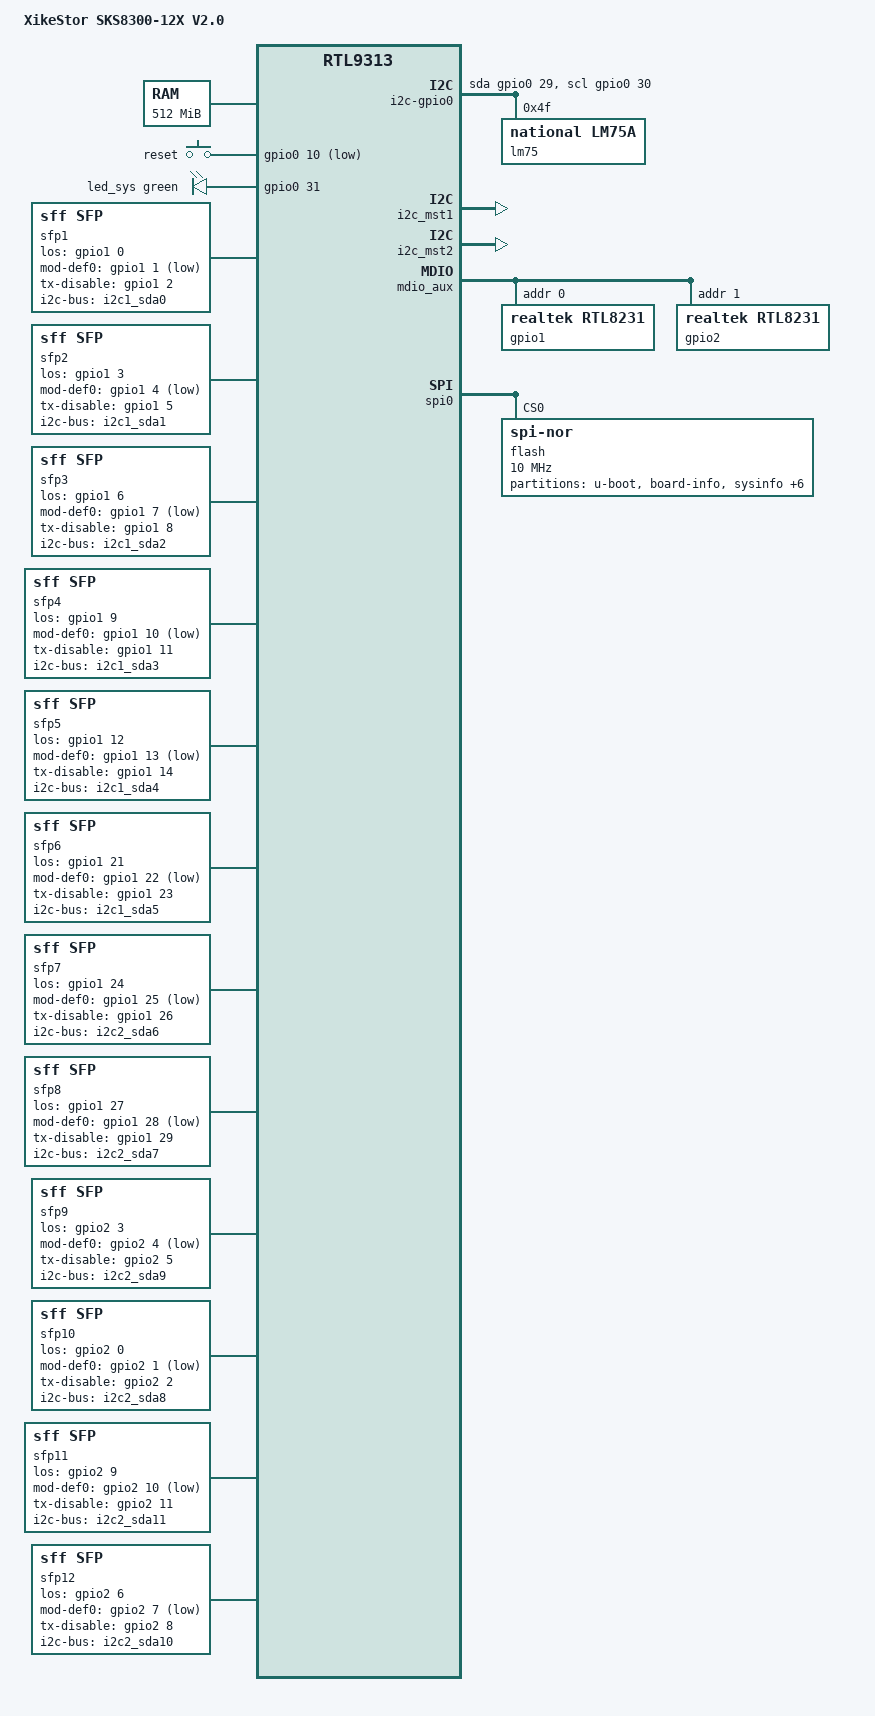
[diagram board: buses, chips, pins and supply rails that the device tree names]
// SPDX-License-Identifier: GPL-2.0-or-later

#include "rtl931x.dtsi"

#include <dt-bindings/input/input.h>
#include <dt-bindings/gpio/gpio.h>
#include <dt-bindings/leds/common.h>
#include <dt-bindings/phy/phy.h>

/ {
        compatible = "xikestor,sks8300-12x-v2", "realtek,rtl9313-soc";
        model = "XikeStor SKS8300-12X V2.0";

        memory@0 {
                device_type = "memory";
                reg = <0x00000000 0x10000000>, /* first 256 MiB */
                      <0x90000000 0x10000000>; /* remaining 256 MiB */
        };

        aliases {
                label-mac-device = &ethernet0;
                led-boot = &led_sys;
                led-failsafe = &led_sys;
                led-running = &led_sys;
                led-upgrade = &led_sys;
        };

        chosen {
                stdout-path = "serial0:115200n8";
                bootargs = "loglevel=4";
        };

        keys {
                compatible = "gpio-keys";

                button-reset {
                        label = "reset";
                        gpios = <&gpio0 10 GPIO_ACTIVE_LOW>;
                        linux,code = <KEY_RESTART>;
                };
        };

        leds {
                compatible = "gpio-leds";

                led_sys: led-0 {
                        gpios = <&gpio0 31 GPIO_ACTIVE_HIGH>;
                        color = <LED_COLOR_ID_GREEN>;
                        function = LED_FUNCTION_STATUS;
                };
        };

        led_set {
                compatible = "realtek,rtl9300-leds";
                active-low;

                /* LED[0]: green | LED[1]: amber */
                led_set0 = <(RTL93XX_LED_SET_10G | RTL93XX_LED_SET_LINK |
                             RTL93XX_LED_SET_ACT)
                            (RTL93XX_LED_SET_2P5G | RTL93XX_LED_SET_1G |
                             RTL93XX_LED_SET_LINK | RTL93XX_LED_SET_ACT)>;
        };

        watchdog1: watchdog {
                compatible = "diodes,pt7a75xx-wdt";
        };

        i2c-gpio0 {
                compatible = "i2c-gpio";
                #address-cells = <1>;
                #size-cells = <0>;

                sda-gpios = <&gpio0 29 GPIO_ACTIVE_HIGH>;
                scl-gpios = <&gpio0 30 GPIO_ACTIVE_HIGH>;

                i2c-gpio,delay-us = <5>;        /* ~100 kHz */
                lm75: sensor@4f {
                        compatible = "national,lm75a";
                        reg = <0x4f>;
                };
        };

        sfp1: sfp-p1 {
                compatible = "sff,sfp";
                i2c-bus = <&i2c1_sda0>;
                los-gpio = <&gpio1 0 GPIO_ACTIVE_HIGH>;
                mod-def0-gpio = <&gpio1 1 GPIO_ACTIVE_LOW>;
                tx-disable-gpio = <&gpio1 2 GPIO_ACTIVE_HIGH>;
                #thermal-sensor-cells = <0>;
        };

        sfp2: sfp-p2 {
                compatible = "sff,sfp";
                i2c-bus = <&i2c1_sda1>;
                los-gpio = <&gpio1 3 GPIO_ACTIVE_HIGH>;
                mod-def0-gpio = <&gpio1 4 GPIO_ACTIVE_LOW>;
                tx-disable-gpio = <&gpio1 5 GPIO_ACTIVE_HIGH>;
                #thermal-sensor-cells = <0>;
        };

        sfp3: sfp-p3 {
                compatible = "sff,sfp";
                i2c-bus = <&i2c1_sda2>;
                los-gpio = <&gpio1 6 GPIO_ACTIVE_HIGH>;
                mod-def0-gpio = <&gpio1 7 GPIO_ACTIVE_LOW>;
                tx-disable-gpio = <&gpio1 8 GPIO_ACTIVE_HIGH>;
                #thermal-sensor-cells = <0>;
        };

        sfp4: sfp-p4 {
                compatible = "sff,sfp";
                i2c-bus = <&i2c1_sda3>;
                los-gpio = <&gpio1 9 GPIO_ACTIVE_HIGH>;
                mod-def0-gpio = <&gpio1 10 GPIO_ACTIVE_LOW>;
                tx-disable-gpio = <&gpio1 11 GPIO_ACTIVE_HIGH>;
                #thermal-sensor-cells = <0>;
        };

        sfp5: sfp-p5 {
                compatible = "sff,sfp";
                i2c-bus = <&i2c1_sda4>;
                los-gpio = <&gpio1 12 GPIO_ACTIVE_HIGH>;
                mod-def0-gpio = <&gpio1 13 GPIO_ACTIVE_LOW>;
                tx-disable-gpio = <&gpio1 14 GPIO_ACTIVE_HIGH>;
                #thermal-sensor-cells = <0>;
        };

        sfp6: sfp-p6 {
                compatible = "sff,sfp";
                i2c-bus = <&i2c1_sda5>;
                los-gpio = <&gpio1 21 GPIO_ACTIVE_HIGH>;
                mod-def0-gpio = <&gpio1 22 GPIO_ACTIVE_LOW>;
                tx-disable-gpio = <&gpio1 23 GPIO_ACTIVE_HIGH>;
                #thermal-sensor-cells = <0>;
        };

        sfp7: sfp-p7 {
                compatible = "sff,sfp";
                i2c-bus = <&i2c2_sda6>;
                los-gpio = <&gpio1 24 GPIO_ACTIVE_HIGH>;
                mod-def0-gpio = <&gpio1 25 GPIO_ACTIVE_LOW>;
                tx-disable-gpio = <&gpio1 26 GPIO_ACTIVE_HIGH>;
                #thermal-sensor-cells = <0>;
        };

        sfp8: sfp-p8 {
                compatible = "sff,sfp";
                i2c-bus = <&i2c2_sda7>;
                los-gpio = <&gpio1 27 GPIO_ACTIVE_HIGH>;
                mod-def0-gpio = <&gpio1 28 GPIO_ACTIVE_LOW>;
                tx-disable-gpio = <&gpio1 29 GPIO_ACTIVE_HIGH>;
                #thermal-sensor-cells = <0>;
        };

        sfp9: sfp-p9 {
                compatible = "sff,sfp";
                i2c-bus = <&i2c2_sda9>;
                los-gpio = <&gpio2 3 GPIO_ACTIVE_HIGH>;
                mod-def0-gpio = <&gpio2 4 GPIO_ACTIVE_LOW>;
                tx-disable-gpio = <&gpio2 5 GPIO_ACTIVE_HIGH>;
                #thermal-sensor-cells = <0>;
        };

        sfp10: sfp-p10 {
                compatible = "sff,sfp";
                i2c-bus = <&i2c2_sda8>;
                los-gpio = <&gpio2 0 GPIO_ACTIVE_HIGH>;
                mod-def0-gpio = <&gpio2 1 GPIO_ACTIVE_LOW>;
                tx-disable-gpio = <&gpio2 2 GPIO_ACTIVE_HIGH>;
                #thermal-sensor-cells = <0>;
        };

        sfp11: sfp-p11 {
                compatible = "sff,sfp";
                i2c-bus = <&i2c2_sda11>;
                los-gpio = <&gpio2 9 GPIO_ACTIVE_HIGH>;
                mod-def0-gpio = <&gpio2 10 GPIO_ACTIVE_LOW>;
                tx-disable-gpio = <&gpio2 11 GPIO_ACTIVE_HIGH>;
                #thermal-sensor-cells = <0>;
        };

        sfp12: sfp-p12 {
                compatible = "sff,sfp";
                i2c-bus = <&i2c2_sda10>;
                los-gpio = <&gpio2 6 GPIO_ACTIVE_HIGH>;
                mod-def0-gpio = <&gpio2 7 GPIO_ACTIVE_LOW>;
                tx-disable-gpio = <&gpio2 8 GPIO_ACTIVE_HIGH>;
                #thermal-sensor-cells = <0>;
        };
};

&i2c_mst1 {
        status = "okay";

        i2c1_sda0: i2c@0 {
                reg = <0>;
        };
        i2c1_sda1: i2c@1 {
                reg = <1>;
        };
        i2c1_sda2: i2c@2 {
                reg = <2>;
        };
        i2c1_sda3: i2c@3 {
                reg = <3>;
        };
        i2c1_sda4: i2c@4 {
                reg = <4>;
        };
        i2c1_sda5: i2c@5 {
                reg = <5>;
        };
};

&i2c_mst2 {
        status = "okay";

        i2c2_sda6: i2c@6 {
                reg = <6>;
        };
        i2c2_sda7: i2c@7 {
                reg = <7>;
        };
        i2c2_sda8: i2c@8 {
                reg = <8>;
        };
        i2c2_sda9: i2c@9 {
                reg = <9>;
        };
        i2c2_sda10: i2c@a {
                reg = <10>;
        };
        i2c2_sda11: i2c@b {
                reg = <11>;
        };
};

&mdio_aux {
        status = "okay";

        gpio1: gpio@0 {
                compatible = "realtek,rtl8231";
                reg = <0>;

                gpio-controller;
                #gpio-cells = <2>;
                gpio-ranges = <&gpio1 0 0 37>;

                led-controller {
                        compatible = "realtek,rtl8231-leds";
                        status = "disabled";
                };
        };

        gpio2: gpio@1 {
                compatible = "realtek,rtl8231";
                reg = <1>;

                gpio-controller;
                #gpio-cells = <2>;
                gpio-ranges = <&gpio2 0 0 37>;

                led-controller {
                        compatible = "realtek,rtl8231-leds";
                        status = "disabled";
                };
        };
};

&spi0 {
        status = "okay";

        flash@0 {
                compatible = "jedec,spi-nor";
                reg = <0>;
                spi-max-frequency = <10000000>;

                /* Delete all V1 partitions completely */
                /delete-node/ partitions;

                partitions {
                        compatible = "fixed-partitions";
                        #address-cells = <1>;
                        #size-cells = <1>;

                        /* LOADER: 0x000000-0x13ffff (1.25MB) */
                        partition@0 {
                                label = "u-boot";
                                reg = <0x0 0x140000>;
                                read-only;
                        };

                        /* BDINFO: 0x140000-0x14ffff (64KB) */
                        partition@140000 {
                                label = "board-info";
                                reg = <0x140000 0x10000>;
                                read-only;

                                nvmem-layout {
                                        compatible = "fixed-layout";
                                        #address-cells = <1>;
                                        #size-cells = <1>;

                                        macaddr_vendor: macaddr@1f1 {
                                                compatible = "mac-base";
                                                reg = <0x1f1 0x6>;
                                                #nvmem-cell-cells = <1>;
                                        };
                                };
                        };

                        /* SYSINFO: 0x150000-0x15ffff (64KB) */
                        partition@150000 {
                                label = "sysinfo";
                                reg = <0x150000 0x10000>;
                                read-only;
                        };

                        /* JFFS2_CFG: 0x160000-0x1fffff (640KB) */
                        partition@160000 {
                                label = "jffs2-cfg";
                                reg = <0x160000 0xa0000>;
                        };

                        /* JFFS2_LOG: 0x200000-0x5fffff (4MB) */
                        partition@200000 {
                                label = "jffs2-log";
                                reg = <0x200000 0x400000>;
                        };

                        /*
                         * NOTE: "rootfs_data" is declared BEFORE runtime1 so that
                         * the explicit 13MB partition is registered ahead of the
                         * mtdsplit_squashfs auto-generated "rootfs_data" inside
                         * runtime1.rootfs. fstools picks the FIRST match in
                         * /proc/mtd, ensuring the 13MB partition becomes /overlay.
                         * Trade-off: the runtime2 dual-bank firmware slot is
                         * sacrificed (no fallback boot image).
                         */

                        /* ROOTFS_DATA (former RUNTIME2): 0x1300000-0x1ffffff (13MB) */
                        partition@1300000 {
                                label = "rootfs_data";
                                reg = <0x1300000 0xd00000>;
                        };

                        /* RUNTIME1: 0x600000-0x12fffff (13MB) */
                        partition@600000 {
                                compatible = "fixed-partitions";
                                label = "runtime1";
                                reg = <0x600000 0xd00000>;
                                #address-cells = <1>;
                                #size-cells = <1>;

                                partition@0 {
                                        label = "kernel";
                                        reg = <0x0 0x500000>;
                                };

                                partition@500000 {
                                        label = "rootfs";
                                        reg = <0x500000 0x800000>;
                                };
                        };
                };
        };
};

&ethernet0 {
        nvmem-cells = <&macaddr_vendor 0>;
        nvmem-cell-names = "mac-address";
};

&switch0 {
        ethernet-ports {
                #address-cells = <1>;
                #size-cells = <0>;

                SWITCH_PORT_SFP(0, 1, 2, 0, 1)
                SWITCH_PORT_SFP(8, 2, 3, 0, 2)
                SWITCH_PORT_SFP(16, 3, 4, 0, 3)
                SWITCH_PORT_SFP(24, 4, 5, 0, 4)
                SWITCH_PORT_SFP(32, 5, 6, 0, 5)
                SWITCH_PORT_SFP(40, 6, 7, 0, 6)
                SWITCH_PORT_SFP(48, 7, 8, 0, 7)
                SWITCH_PORT_SFP(50, 8, 9, 0, 8)
                SWITCH_PORT_SFP(52, 10, 10, 0, 10)
                SWITCH_PORT_SFP(53, 9, 11, 0, 9)
                SWITCH_PORT_SFP(54, 12, 12, 0, 12)
                SWITCH_PORT_SFP(55, 11, 13, 0, 11)

                /* CPU port */
                port@56 {
                        ethernet = <&ethernet0>;
                        reg = <56>;
                        phy-mode = "internal";
                        fixed-link {
                                speed = <1000>;
                                full-duplex;
                        };
                };
        };
};

&port0  { phy-mode = "10gbase-r"; };
&port8  { phy-mode = "10gbase-r"; };
&port16 { phy-mode = "10gbase-r"; };
&port24 { phy-mode = "10gbase-r"; };
&port32 { phy-mode = "10gbase-r"; };
&port40 { phy-mode = "10gbase-r"; };
&port48 { phy-mode = "10gbase-r"; };
&port50 { phy-mode = "10gbase-r"; };
&port52 { phy-mode = "10gbase-r"; };
&port53 { phy-mode = "10gbase-r"; };
&port54 { phy-mode = "10gbase-r"; };
&port55 { phy-mode = "10gbase-r"; };

&serdes2 { tx-polarity = <PHY_POL_INVERT>; };
&serdes3 { tx-polarity = <PHY_POL_INVERT>; };
&serdes4 { tx-polarity = <PHY_POL_INVERT>; };
&serdes5 { tx-polarity = <PHY_POL_INVERT>; };
&serdes6 { tx-polarity = <PHY_POL_INVERT>; };
&serdes7 { tx-polarity = <PHY_POL_INVERT>; };
&serdes8 { tx-polarity = <PHY_POL_INVERT>; };
&serdes9 { tx-polarity = <PHY_POL_INVERT>; };
&serdes10 { tx-polarity = <PHY_POL_INVERT>; };
&serdes11 { tx-polarity = <PHY_POL_INVERT>; };
&serdes12 { tx-polarity = <PHY_POL_INVERT>; };
&serdes13 { tx-polarity = <PHY_POL_INVERT>; };
